# psoc6_01 register map
Vendor: Cypress Semiconductor; Series: psoc6_01; File version: 1.0
CPU: CM4 r0p1, little endian, MPU, FPU, VTOR, 3 interrupt priority bits
Registers are 32-bit, read-write, reset 0x0 unless marked. A register's access mark holds for its fields unless they carry their own. Offsets are from the block's base; [hi:lo] are bit positions; lines under a group give offsets from that group; {n}, {i} and the like mark numbered series; <NAME> marks a mode.

## BLE (part 5 of 5) — Bluetooth Low Energy Subsystem
Base 0x403C0000
0x1F000 BLESS group — Bluetooth Low Energy Subsystem Miscellaneous
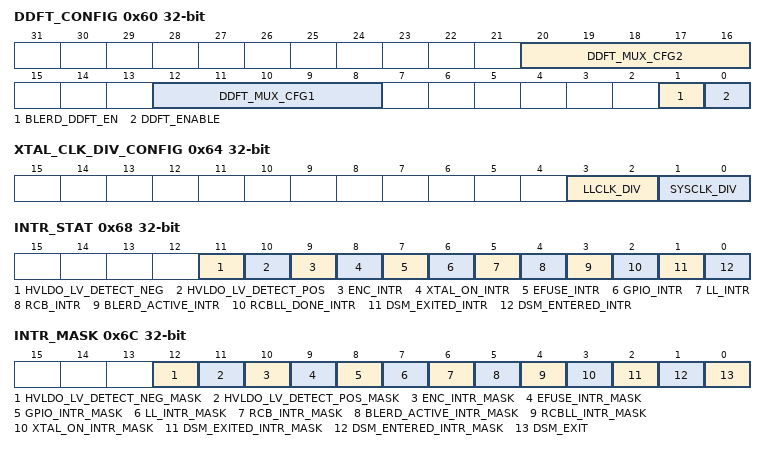
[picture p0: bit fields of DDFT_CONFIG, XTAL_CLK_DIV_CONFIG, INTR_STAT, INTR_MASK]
  0x60 DDFT_CONFIG — BLESS DDFT configuration register
    [20:16] DDFT_MUX_CFG2 — dbg_mux_pin2 selection, combine with BLERD and BLESS 5'h00 blerd_ddft_out[1] 5'h01 rcb_rx_fifo_empty 5'h02 ll_decode_rxdata 5'h03 dbus_tx_en 5'h04 fw_clk_en 5'h05 interrupt_ll_n 5'h06 llh_st_sm 5'h07 llh_st_dsm 5'h08 proc_rx_en 5'h09 rssi_rx_done 5'h0A rx_2mbps 5'h0B rcb_ll_ctrl 5'h0C hv_ldo_byp_n 5'h0D reset_deassert 5'h0E rcb_intr 5'h0F rcb_ll_intr 5'h10 hv_ldo_en_mt (act_stdbyb) 5'h11 hv_ldo_lv_detect_raw 5'h12 bless_rcb_data_in 5'h13 bless_xtal_en_out 5'h14 bless_isolate_n_out 5'h15 bless_reset_n_out 5'h16 bless_ret_ldo_ol_hv_out 5'h17 bless_txd_rxd_out 5'h18 tx_rx_ctrl_sel 5'h19 bless_bpktctl_cy 5'h1A efuse_cs_out 5'h1B efuse_pgm_out 5'h1C efuse_sclk_out 5'h1D hv_ldo_lv_detect_mt 5'h1E enable_ldo 5'h1F enable_ldo_dly
    [12:8] DDFT_MUX_CFG1 — dbg_mux_pin1 selection, combine with BLERD and BLESS 5'h00 blerd_ddft_out[0] 5'h01 rcb_tx_fifo_empty 5'h02 hv_ldo_lv_detect_raw 5'h03 dbus_rx_en 5'h04 1'b0 5'h05 clk_switch_to_sysclk 5'h06 ll_clk_en_sync 5'h07 dsm_entry_stat 5'h08 proc_tx_en 5'h09 rssi_read_start 5'h0A tx_2mbps 5'h0B rcb_bus_busy 5'h0C hv_ldo_en_mt (act_stdbyb) 5'h0D ll_eco_clk_en 5'h0E blerd_reset_assert 5'h0F hv_ldo_byp_n 5'h10 hv_ldo_lv_detect_mt 5'h11 enable_ldo 5'h12 enable_ldo_dly 5'h13 bless_rcb_le_out 5'h14 bless_rcb_clk_out 5'h15 bless_dig_ldo_on_out 5'h16 bless_act_ldo_en_out 5'h17 bless_clk_en_out 5'h18 bless_buck_en_out 5'h19 bless_ret_switch_hv_out 5'h1A efuse_rw_out 5'h1B efuse_avdd_out 5'h1C efuse_config_efuse_mode 5'h1D bless_dbus_tx_en_pad 5'h1E bless_bpktctl_rd 5'h1F 1'b0
    [1] BLERD_DDFT_EN — Enables the DDFT inputs from CYBLERD55 chip 1: DDFT inputs are enabled 0: DDFT inputs are disabled
    [0] DDFT_ENABLE — Enables the DDFT output from BLESS 1: DDFT is enabled 0: DDFT is disabled
  0x64 XTAL_CLK_DIV_CONFIG — Crystal clock divider configuration register
    [3:2] LLCLK_DIV — Link Layer clock pre-divider value. The 24 MHz crystal clock is divided to generate the Link Layer clock. 0: NO_DIV: LLCLK= XTALCLK/1 1: DIV_BY_2: LLCLK= XTALCLK/2 2: DIV_BY_4: LLCLK= XTALCLK/4 3: DIV_BY_8: LLCLK= XTALCLK/8
    [1:0] SYSCLK_DIV — System clock pre-divider value. The 24 MHz crystal clock is divided to generate the system clock. 0: NO_DIV: SYSCLK= XTALCLK/1 1: DIV_BY_2: SYSCLK= XTALCLK/2 2: DIV_BY_4: SYSCLK= XTALCLK/4 3: DIV_BY_8: SYSCLK= XTALCLK/8
  0x68 INTR_STAT — Link Layer interrupt status register
    [11] HVLDO_LV_DETECT_NEG — This interrupt is set on HVLDO LV Detector Fall edge. There is a 1cycle AHB clock glitch filter on the HVLDO LV Detector output
    [10] HVLDO_LV_DETECT_POS — This interrupt is set on HVLDO LV Detector Rise edge. There is a 1cycle AHB clock glitch filter on the HVLDO LV Detector output
    [9] ENC_INTR ro — Encryption Interrupt Triggered
    [8] XTAL_ON_INTR — enabled crystal stable signal rising edge interrupt. The interrupt can be cleared by writing one into this location.
    [7] EFUSE_INTR — This bit when set by efuse controller logic when the efuse read/write is completed
    [6] GPIO_INTR — GPIO interrupt
    [5] LL_INTR ro — LL controller interrupt - Refer to EVENT_INTR register
    [4] RCB_INTR ro — RCB controller Interrupt - Refer to RCB_INTR_STAT register
    [3] BLERD_ACTIVE_INTR — CYBLERD55 is in active mode. RF is active
    [2] RCBLL_DONE_INTR ro — RCB transaction Complete
    [1] DSM_EXITED_INTR — On a firmware request to LL to exit from Deep Sleep Mode, working on LF clock, LL transitions from Deep Sleep Mode and asserts this interrupt when the Deep Sleep clock gater is turned ON. The interrupt can be cleared by writing one into this location.
    [0] DSM_ENTERED_INTR — On a firmware request to LL to enter into state machine, working on LF clock, LL transitions into Deep Sleep Mode and asserts this interrupt. The interrupt can be cleared by writing one into this location.
  0x6C INTR_MASK — Link Layer interrupt mask register
    [12] HVLDO_LV_DETECT_NEG_MASK — Mask for HVLDO LV Detector Fall edge interrupt
    [11] HVLDO_LV_DETECT_POS_MASK — Mask for HVLDO LV Detector Rise edge interrupt
    [10] ENC_INTR_MASK — Mask for Encryption interrupt
    [9] EFUSE_INTR_MASK — This bit enables the efuse interrupt to firmware
    [8] GPIO_INTR_MASK — Mask for GPIO interrupt
    [7] LL_INTR_MASK — Mask for LL interrupt
    [6] RCB_INTR_MASK — Mask for RCB interrupt
    [5] BLERD_ACTIVE_INTR_MASK — Mask for CYBLERD55 Active Interrupt
    [4] RCBLL_INTR_MASK — Mask for RCBLL interrupt
    [3] XTAL_ON_INTR_MASK — Masks the Crystal Stable Interrupt, when disabled.
    [2] DSM_EXITED_INTR_MASK — Masks the DSM Exited Interrupt, when disabled.
    [1] DSM_ENTERED_INTR_MASK — Masks the DSM Entered Interrupt, when disabled.
    [0] DSM_EXIT — When the Link Layer is in Deep Sleep Mode, firmware can set this bit to wake the Link Layer.
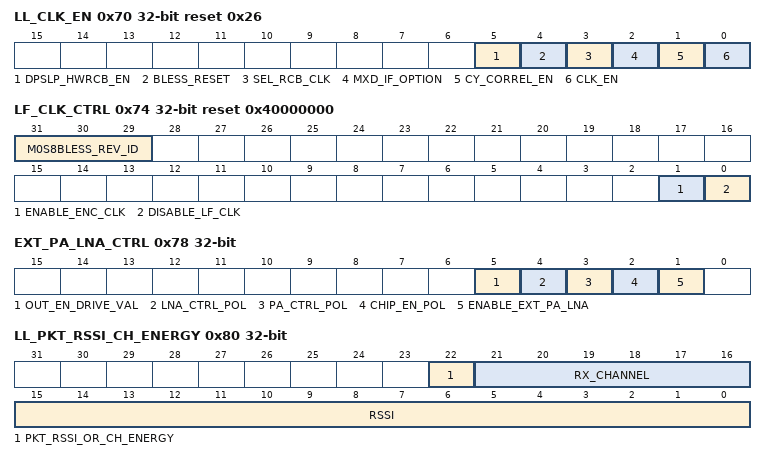
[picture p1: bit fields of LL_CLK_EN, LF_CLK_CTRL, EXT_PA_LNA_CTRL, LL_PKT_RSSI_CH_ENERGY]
  0x70 LL_CLK_EN reset 0x26 — Link Layer primary clock enable
    [5] DPSLP_HWRCB_EN — Controls the DPSLP entry and exit writes to RD and controls the active domain reset and clock. 1 - LL HW controls the RD active domain reset and clock. 0 - The RD active domain reset and clock. Must be controlled by the FW
    [4] BLESS_RESET — 0: No Soft Reset 1: Initiate Soft Reset Setting this bit will reset entire BLESS_VER3
    [3] SEL_RCB_CLK — 0: AHB clock (clk_sys) is used as the clock for RCB access 1: LL clock (clk_eco) is used as the clock for RCB access
    [2] MXD_IF_OPTION — 1: MXD IF option 0: CYBLERD55 correlates Access Code 0: MXD IF option 1: LL correlates Access Code
    [1] CY_CORREL_EN — If MXD_IF option is 1, this bit needs to be set to enable configuring the correlator through BLELL.DPLL_CONFIG register
    [0] CLK_EN — Set this bit 1 to enable the clock to Link Layer.
  0x74 LF_CLK_CTRL reset 0x40000000 — BLESS LF clock control and BLESS revision ID indicator
    [31:29] M0S8BLESS_REV_ID ro — Indicates the m0s8bless IP revision.
    [1] ENABLE_ENC_CLK — This bit is used to enable the clock to the encryption engine 0 - Disable the clock to ENC engine 1 - Enable the clock to ENC engine
    [0] DISABLE_LF_CLK — When set to 1, gates the LF clock input to the Link Layer. Ths is done for extended DSM mode where the DSM state machine needs to be forzen to prevent a default auto exit.
  0x78 EXT_PA_LNA_CTRL — External TX PA and RX LNA control
    [5] OUT_EN_DRIVE_VAL — Configures the drive value on the output enables of PA, LNA and CHI_EN signals 0 - drive 0 on the output enable signals 1 - drive 1 on the output enable signals
    [4] LNA_CTRL_POL — Controls the polarity of the LNA control signal 0 - High enable, low disable 1 - Low enable, High disable
    [3] PA_CTRL_POL — Controls the polarity of the PA control signal 0 - High enable, low disable 1 - Low enable, High disable
    [2] CHIP_EN_POL — Controls the polarity of the chip enable control signal 0 - High enable, low disable 1 - Low enable, High disable
    [1] ENABLE_EXT_PA_LNA — When set to 1, enables the external PA & LNA
  0x80 LL_PKT_RSSI_CH_ENERGY ro — Link Layer Last Received packet RSSI/Channel energy and channel number
    [22] PKT_RSSI_OR_CH_ENERGY — This field indicates if the captured RSSI is for a received packet or is the channel energy
    [21:16] RX_CHANNEL — This field indicates the last channel for which the RSSI is captured
    [15:0] RSSI — This field captures the RSSI of the packet when a packet reception is complete or gives the Channel energy when a Receive cycle is over without packet reception.
  0x84 BT_CLOCK_CAPT ro — BT clock captured on an LL DSM exit
    [15:0] BT_CLOCK — This field captures the LF BT clock captured on an LL DSM exit. This register is valid only when MT_STATUS.LL_CLK_STATE is set. This value may be used to manage the low power entry.
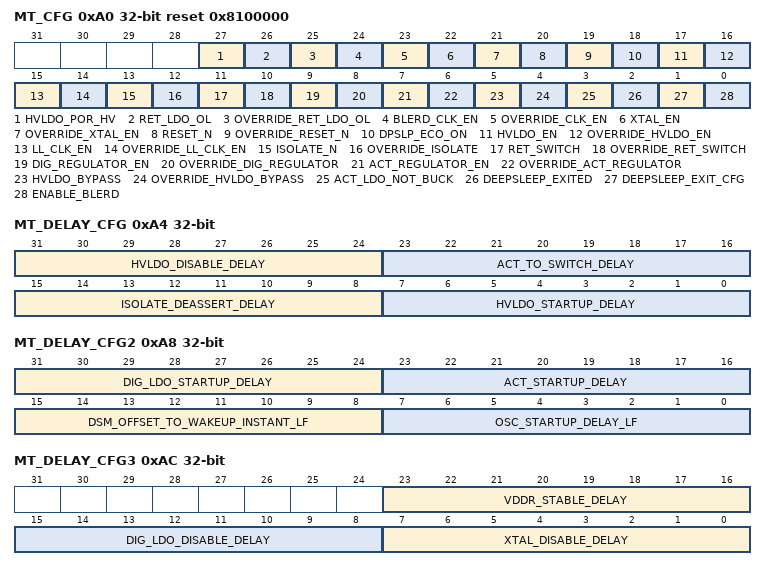
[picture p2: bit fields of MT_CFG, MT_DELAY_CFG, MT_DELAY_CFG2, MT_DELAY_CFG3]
  0xA0 MT_CFG reset 0x8100000 — MT Configuration Register
    [27] HVLDO_POR_HV — Reset for HVLDO 1'b1 - HVLDO Disabled 1'b0 - HVLDO Enabled
    [26] RET_LDO_OL — Overrie value for CYBLERD55 RET_LDO_OL_HV
    [25] OVERRIDE_RET_LDO_OL — This register should be set to override the HW generated RET_LDO_OL_HV to CYBLERD55. When set CLK_EN is used.
    [24] BLERD_CLK_EN — Overrie value for CYBLERD55 CLK_EN
    [23] OVERRIDE_CLK_EN — This register should be set to override the HW generated CLK_EN to CYBLERD55. When set CLK_EN is used.
    [22] XTAL_EN — Overrie value for CYBLERD55 XTAL_EN
    [21] OVERRIDE_XTAL_EN — This register should be set to override the HW generated XTAL_EN to CYBLERD55. When set XTAL_EN is used.
    [20] RESET_N — Overrie value for CYBLERD55 RESET_N
    [19] OVERRIDE_RESET_N — This register should be set to override the HW generated reset to CYBLERD55. When set RESET_N is used.
    [18] DPSLP_ECO_ON — This bit when set indicates that ECO clock should be kept on even in BLESS DPSLP. This bit must be toggled only when the Link Layer is active.
    [17] HVLDO_EN — Overrie value for HVLDO enable 1'b1: switch to Active LDO 1'b0: switch to standby LDO
    [16] OVERRIDE_HVLDO_EN — This register should be set to override the HW generated enable to HVLSO. When set HVLDO_EN is used.
    [15] LL_CLK_EN — Override value for LL Clock gate
    [14] OVERRIDE_LL_CLK_EN — This register should be set to override the HW generated ECO Clock gate. When set LL_CLK_EN is used to gate the clock
    [13] ISOLATE_N — Override value for isolation to CYBLERD55
    [12] OVERRIDE_ISOLATE — This register should be set to override the HW generated isolation signal to CYBLERD55. When set ISOLATE_N is driven to the IP
    [11] RET_SWITCH — Override value for RET_SWITCH
    [10] OVERRIDE_RET_SWITCH — This register should be set to override the HW generated signal to the retention switch of CYBLERD55. When set OVERRIDE_RET_SWITCH is driven to the IP
    [9] DIG_REGULATOR_EN — Override value for digital regulator of CYBLERD55
    [8] OVERRIDE_DIG_REGULATOR — This register should be set to override the HW generated signal to Digital regulator of CYBLERD55. When set DIG_REGULATOR_EN is driven to CYBLERD55
    [7] ACT_REGULATOR_EN — Override value for ACT_LDO_EN/BUCK_EN
    [6] OVERRIDE_ACT_REGULATOR — This register should be set to override the HW generated signal to enable ACTIVE_LDO/BUCK. When set ACT_REGULATOR_EN is driven to CYBLERD55
    [5] HVLDO_BYPASS — Override value for HVLDO BYPASS 1'b0: bypass the HVLDO 1'b1: Do not bypass the HVLDO
    [4] OVERRIDE_HVLDO_BYPASS — This register should be set to override the HW generated signal to HVLDO. When set HVLDO_BYPASS is driven to the IP
    [3] ACT_LDO_NOT_BUCK — This register bit specifies whether the Active LDO or BUCK in CYBLERD55 is used in active mode
    [2] DEEPSLEEP_EXITED — This register bit is used by FW to indicate that PSoC is out of DeepSleep 1'b0 - PSoC in DeepSleep 1'b1 - PSoC out of DeepSleep This bit is cleared by HW on exit from DPSLP
    [1] DEEPSLEEP_EXIT_CFG — This register bit indicates the source for PSoC DeepSleep exit to BLESS 1'b0 - act_power_good from SRSS indicates PSoC DeepSleep exit 1'b1 - MT_CFG.DEEPSLEEP_EXITED indicates PSoC DeepSleep exit
    [0] ENABLE_BLERD — This register bit needs to be set to enable CYBLERD55 1'b1 - CYBLERD55 enabled 1'b0 - CYBLERD55 disabled On power up this bit needs to be set to make CYBLERD55 active.
  0xA4 MT_DELAY_CFG — MT Delay configuration for state transitions
    [31:24] HVLDO_DISABLE_DELAY — This register specifies the time from disabling XTAL to switching of the HVLDO.
    [23:16] ACT_TO_SWITCH_DELAY — This register specifies the time from assertion of ISOLATE_N to switching the CYBLERD55 logic to Retention LDO
    [15:8] ISOLATE_DEASSERT_DELAY — This register specifies the time from switching the CYBLERD55 logic to Active regulator to removal of ISOLATE_N
    [7:0] HVLDO_STARTUP_DELAY — This register specifies the startup delay for the HVLDO interms of number of LF Clock cycles. FW has to program this register based on the selected LF clock frequency
  0xA8 MT_DELAY_CFG2 — MT Delay configuration for state transitions
    [31:24] DIG_LDO_STARTUP_DELAY — This register specifes the Digital LDO startup time in CYBLERD55.The delay is in terms of LF Clock cycles. FW has to program this register based on the selected LF clock frequency. The logic in CYBLERD55 is switched to Active mode Regulator after this (ACT_STARTUP_DELAY + DIG_LDO_STARTUP_DELAY)
    [23:16] ACT_STARTUP_DELAY — This register specifes the Active Regulator startup time in CYBLERD55. The delay is in terms of LF Clock cycles. FW has to program this register based on the selected LF clock frequency. The digital LDO will be turned on after this time elapses
    [15:8] DSM_OFFSET_TO_WAKEUP_INSTANT_LF — This register specifies the pre-processing time required in Link Layer. This is esentially the time from CLK_EN (ungating clock in CYBLERD55) to the time when logic in CYBLERD55 is switched to Active mode Regulator.The delay is in terms of LF Clock cycles. FW has to program this register based on the selected LF clock frequency. This is equivalent to Link Layer register WAKEUP_CONFIG.DSM_OFFSET_TO_WAKEUP_INSTANT_LF, but is specified in LF cycles.
    [7:0] OSC_STARTUP_DELAY_LF — This register specifies the time for OSC Startup. After this delay, clock is enabled to the link layer. Clock is enabled after OSC_STARTUP_DELAY + 1 LF clock cycles. If PSoC was in DPSLP when XTAL is enabled, then the wakeup delay will be OSC_STARTUP_DELAY + 1 + PSoC Wakeup time. Minimum value to be programmed in 1. This is equivalent to Link Layer register WAKEUP_CONFIG.OSC_STARTUP_DELAY, but is specified in LF cycles
  0xAC MT_DELAY_CFG3 — MT Delay configuration for state transitions
    [23:16] VDDR_STABLE_DELAY — This field holds the delay after HVLDO Startup to VDDR Stable. Refer to memo AKK-410
    [15:8] DIG_LDO_DISABLE_DELAY — This field holds the delay from the time of diabling Digital LDO to the time at which ACTIVE regulator is disabled
    [7:0] XTAL_DISABLE_DELAY — This register specifies the time from switching of logic to Retention LDO in CYBLERD55 to XTAL Disable. This should include the post processing time The delay is in terms of LF Clock cycles. FW has to program this register based on the selected LF clock frequency. At the minimum XTAL_DISABLE_DELAY should be the sum of DIG_LDO_DISABLE_DELAY and the powerdown time of ACTIVE_LDO
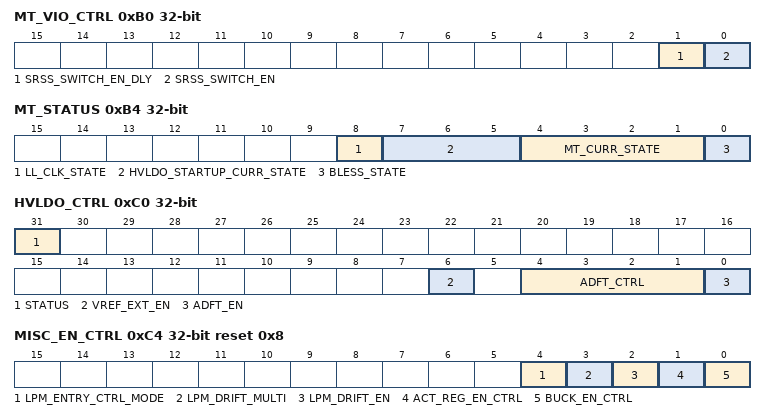
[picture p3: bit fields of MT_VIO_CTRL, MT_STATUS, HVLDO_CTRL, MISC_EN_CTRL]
  0xB0 MT_VIO_CTRL — MT Configuration Register to control VIO switches
    [1] SRSS_SWITCH_EN_DLY — Enable to turn on HVLDO (All legs). This must be enabled 64us after enabling SRSS_SWITCH_EN 1'b0 - Switch is turned off 1'b1 - Switch is turned on
    [0] SRSS_SWITCH_EN — Enable to turn on HVLDO (One leg) 1'b0 - Switch is turned off 1'b1 - Switch is turned on
  0xB4 MT_STATUS ro
    [8] LL_CLK_STATE — This bit indicates when the Link Layer registers are accessible upon a DSM exit. This bit should not be used after a DSM entry command has been issued. 1'b0 - Link Layer clock is not available 1'b1 - Link Layer clock is active
    [7:5] HVLDO_STARTUP_CURR_STATE — This register reflects the current state of the HVLDO Startup FSM 3'h0 - HVLDO_OFF 3'h1 - HVLDO_WAIT 3'h2 - HVLDO_SAMPLE 3'h3 - HVLDO_ENABLED 3'h4 - HVLDO_SET_BYPASS
    [4:1] MT_CURR_STATE — This register reflects the current state of the MT FSM 4'h0 - IDLE 4'h1 - BLERD_DEEPSLEEP 4'h2 - HVLDO_STARTUP 4'h3 - WAIT_CLK 4'h4 - BLERD_IDLE 4'h5 - SWITCH_EN 4'h6 - ACTIVE 4'h7 - ISOLATE 4'h8 - WAIT_IDLE 4'h9 - XTAL_DISABLE 4'hA - HVLDO_DISABLE
    [0] BLESS_STATE — 1'b0 - BLESS in DPSLP state 1'b1 - BLESS in ACTIVE state
  0xB8 PWR_CTRL_SM_ST ro — Link Layer Power Control FSM Status Register
    [3:0] PWR_CTRL_SM_CURR_STATE — This register reflects the current state of the LL Power Control FSM 4'h0 - IDLE 4'h1 - SLEEP 4'h2 - DEEP_SLEEP 4'h4 - WAIT_OSC_STABLE 4'h5 - INTR_GEN 4'h6 - ACTIVE 4'h7 - REQ_RF_OFF
  0xC0 HVLDO_CTRL — HVLDO Configuration register
    [31] STATUS ro — hvldo LV detect status
    [6] VREF_EXT_EN — Vref ext input enable.
    [4:1] ADFT_CTRL — ADFT select
    [0] ADFT_EN — ADFT enable
  0xC4 MISC_EN_CTRL reset 0x8 — Radio Buck and Active regulator enable control
    [4] LPM_ENTRY_CTRL_MODE — Controls the LPM entry control mode 1 - LPM can be entered in the same slot as the previous LPM exit 0 - LPM must not be entered in the same slot or the subsequent slot as the last LPM exit
    [3] LPM_DRIFT_MULTI — Controls the LPM drift multi level compensation. 1 - Enables the LPM drift multi comp 0 - Disables the LPM drift multi comp
    [2] LPM_DRIFT_EN — Controls the LPM drift calculation. 1 - Enables the LPM drift mod 0 - Disables the LPM drift mod
    [1] ACT_REG_EN_CTRL — Active regulator enable control. This must be programmed before enabling the Radio. 1'b0 - Active regulator enable output to radio is tied to 0 1'b1 - Active regulator enable output to radio is controlled from Mode transition FSM
    [0] BUCK_EN_CTRL — Buck enable control. This must be programmed before enabling the Radio. 1'b1 - Buck enable output to radio is tied to 0 1'b0 - Buck enable output to radio is controlled from Mode transition FSM
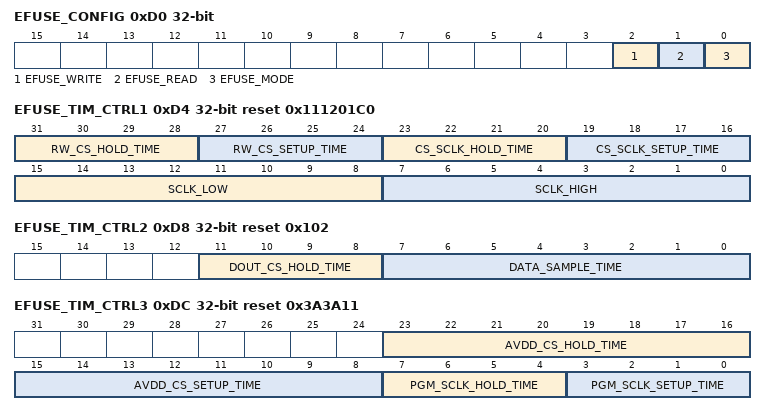
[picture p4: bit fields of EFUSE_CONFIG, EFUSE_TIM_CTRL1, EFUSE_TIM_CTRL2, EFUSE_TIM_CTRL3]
  0xD0 EFUSE_CONFIG — EFUSE mode configuration register
    [2] EFUSE_WRITE — This bit when set by firmware enables the write to EFUSE macro. It is cleared when the efuse write is completed
    [1] EFUSE_READ — This bit when set by firmware enables the read from EFUSE macro. It is cleared when the efuse read is completed
    [0] EFUSE_MODE — This register enables the efuse mode in m0s8bless_ver3
  0xD4 EFUSE_TIM_CTRL1 reset 0x111201C0 — EFUSE timing control register (common for Program and Read modes)
    [31:28] RW_CS_HOLD_TIME — This field decides hold time between RW & CS (THR_RW: in read mode) or RW & AVDD (THP_RW: in Program mode). THR_RW: RW to CS hold time out of Read mode THP_RW: RW to AVDD hold time out of program mode
    [27:24] RW_CS_SETUP_TIME — This field decides setup time between RW & CS (TSR_RW: in read mode) or RW & AVDD (TSP_RW: in Program mode). TSR_RW: RW to CS setup time into Read mode TSP_RW: RW to AVDD setup time into program mode
    [23:20] CS_SCLK_HOLD_TIME — This register specifies the hold time between CS and SCLK (THR_CLK)
    [19:16] CS_SCLK_SETUP_TIME — This register specifies the setup time between CS and SCLK (TSR_CLK)
    [15:8] SCLK_LOW — Duration of SCLK LOW (TCLKP_R) or TCKLP_P
    [7:0] SCLK_HIGH — Decides the duration of TPGM (in Program mode) or TCKHP (in Read mode) TPGM: Burning Time TCKHP : SCLK high Period
  0xD8 EFUSE_TIM_CTRL2 reset 0x102 — EFUSE timing control Register (for Read)
    [11:8] DOUT_CS_HOLD_TIME — Wait time DOUT to CS hold time out of read mode (TDQH)
    [7:0] DATA_SAMPLE_TIME — This register specifies the time for data sampling from SCLK HIGH (TCKDQ_H)
  0xDC EFUSE_TIM_CTRL3 reset 0x3A3A11 — EFUSE timing control Register (for Program)
    [23:16] AVDD_CS_HOLD_TIME — AVDD to CS hold time out of program mode (THP_AVDD_CS)
    [15:8] AVDD_CS_SETUP_TIME — AVDD to CS setup time into program mode (TSP_AVDD_CS)
    [7:4] PGM_SCLK_HOLD_TIME — PGM to SCLK hold time (TH_PGM)
    [3:0] PGM_SCLK_SETUP_TIME — PGM to SCLK setup time (TS_PGM) PGM_SCLK_SETUP_TIME <CS_SCLK_SETUP_TIME
  0xE0 EFUSE_RDATA_L ro — EFUSE Lower read data
    [31:0] DATA — This register has the read value from the Efuse macro, fuse bits[31:0]
  0xE4 EFUSE_RDATA_H ro — EFUSE higher read data
    [31:0] DATA — This register has the read value from the Efuse macro, fuse bits[63:32]
  0xE8 EFUSE_WDATA_L — EFUSE lower write word
    [31:0] DATA — This register has the write value to the Efuse macro, fuse bits[31:0]
  0xEC EFUSE_WDATA_H — EFUSE higher write word
    [31:0] DATA — This register has the write value to the Efuse macro, fuse bits[63:32]
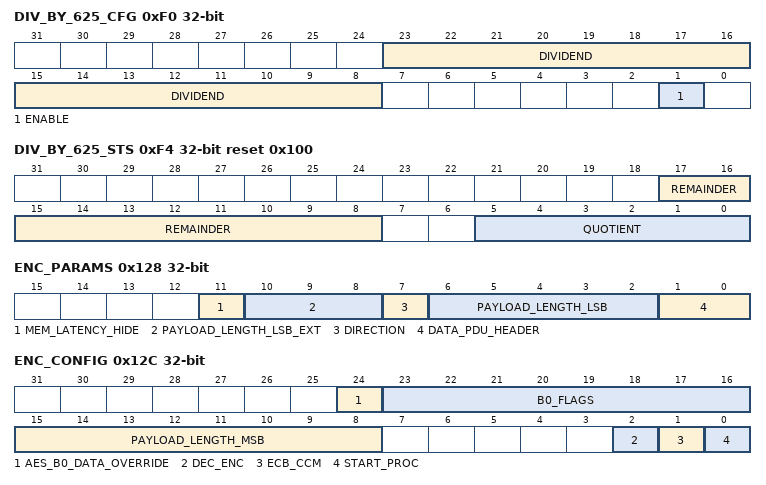
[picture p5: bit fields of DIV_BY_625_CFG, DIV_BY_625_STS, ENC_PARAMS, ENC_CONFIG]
  0xF0 DIV_BY_625_CFG — Divide by 625 for FW Use
    [23:8] DIVIDEND — This field holds the dividend
    [1] ENABLE — This bit enables the divider for use by FW 1'b0 - divider used by LL 1'b1 - divider can be used by FW This divider can only be used in MMMS mode. Do not enable for legacy operation
  0xF4 DIV_BY_625_STS ro reset 0x100 — Output of divide by 625 divider
    [17:8] REMAINDER — Remainder value from the divider. Available 1 cycle after dividend is programmed.
    [5:0] QUOTIENT — Quotient value from the divider. Available 1 cycle after dividend is programmed.
  0x100 PACKET_COUNTER0
    [31:0] PACKET_COUNTER_LOWER — Lower 32-bits of the packet counter value passed as part of Nonce for the packet to be encrypted.
  0x104 PACKET_COUNTER2
    [7:0] PACKET_COUNTER_UPPER — Upper 8 bits of the packet counter value passed as part of Nonce for the packet to be encrypted.
  0x108 IV_MASTER0 — Master Initialization Vector 0
    [31:0] IV_MASTER — This is the IVm field, which contains the master's portion of the initialization vector.
  0x10C IV_SLAVE0 — Slave Initialization Vector 0
    [31:0] IV_SLAVE — This is the IVs field, which contains the slave's portion of the initialization vector.
  {0x110+4j} ENC_KEY[{j}] (j=0..3) wo — Encryption Key register 0-3
    [31:0] ENC_KEY — The encryption key / session key which is used in ECB encryption, CCM encryption and CCM decryption.
  0x120 MIC_IN0 — MIC input register
    [31:0] MIC_IN — This is the MIC field used for CCM decryption.
  0x124 MIC_OUT0 ro — MIC output register
    [31:0] MIC_OUT — This is the MIC generated during CCM encryption.
  0x128 ENC_PARAMS — Encryption Parameter register
    [11] MEM_LATENCY_HIDE — Controls the encryption memory access mode. Valid only when DLE is enabled. 0 - The AES is idle while memory fetch/store in progress. 1- The AES is pipelined while memory fetch/store in progress.
    [10:8] PAYLOAD_LENGTH_LSB_EXT — 3 Most significant bits of the LS byte of the length of the input data. Valid only when DLE is enabled. When DLE is enabled total ENC payload length = {PAYLOAD_LENGTH_LSB_EXT, PAYLOAD_LENGTH_LSB}
    [7] DIRECTION — The directionBit shall be set to '1' for Data Channel PDUs sent by the master and set to '0' for Data Channel PDUs sent by the slave.
    [6:2] PAYLOAD_LENGTH_LSB — Length of the input data.
    [1:0] DATA_PDU_HEADER — LLID of the packet.
  0x12C ENC_CONFIG — Encryption Configuration
    [24] AES_B0_DATA_OVERRIDE — Configuration to use B0 DATA provided by FW for CCM computation
    [23:16] B0_FLAGS — LS byte of the input data when B0 needs to be completely configurable. Valid only when AES_B0_DATA_OVERRIDE is enabled.
    [15:8] PAYLOAD_LENGTH_MSB — MS byte of the length of the input data when B0 needs to be completely configurable. Valid only when AES_B0_DATA_OVERRIDE is enabled. When AES_B0_DATA_OVERRIDE is enabled total ENC payload length = {PAYLOAD_LENGTH_MSB, PAYLOAD_LENGTH_MSB, PAYLOAD_LENGTH}
    [2] DEC_ENC — Decryption/Encryption 0 - Encrypt 1 - Decrypt
    [1] ECB_CCM — 0 - CCM 1 - ECB
    [0] START_PROC — 1 Start the AES processing
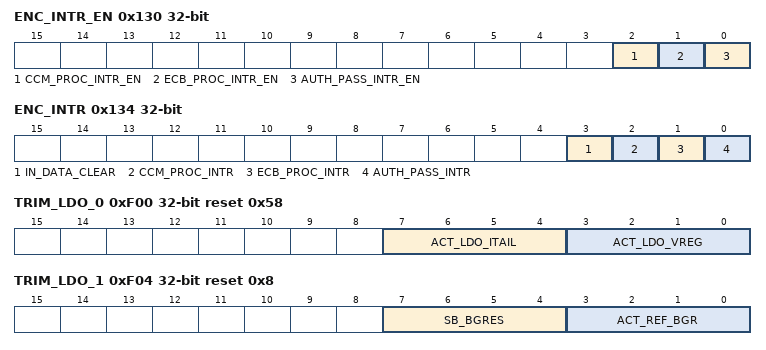
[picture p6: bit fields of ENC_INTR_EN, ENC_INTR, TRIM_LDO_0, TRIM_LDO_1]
  0x130 ENC_INTR_EN — Encryption Interrupt enable
    [2] CCM_PROC_INTR_EN — CCM processed interupt enable 0 - Disable 1 - Enable
    [1] ECB_PROC_INTR_EN — ECB processed interrupt enable 0 - Disable 1 - Enable
    [0] AUTH_PASS_INTR_EN — Authentication interrupt enable 0 - Disable 1 - Enable
  0x134 ENC_INTR — Encryption Interrupt status and clear register
    [3] IN_DATA_CLEAR — Clears the input data. Used for Zero padding of encryption for less than block sized data.
    [2] CCM_PROC_INTR — CCM processed interrupt. Writing 1 to this register clears the interrupt
    [1] ECB_PROC_INTR — ECB processed interrupt. Writing 1 to this register clears the interrupt.
    [0] AUTH_PASS_INTR — Authentication interrupt. 0x1- indicates MIC matched 0x0 -indicated MIC mismatched Writing 1 to this register clears the interrupt.
  {0x140+4j} B1_DATA_REG[{j}] (j=0..3) — Programmable B1 Data register (0-3)
    [31:0] B1_DATA — Programmable B1 Data register
  0x150 ENC_MEM_BASE_ADDR — Encryption memory base address
    [31:0] ENC_MEM — Data values written to Enc memory are written as 16-bit wide data. This memory is valid only if DLE is set.
  0xF00 TRIM_LDO_0 reset 0x58 — LDO Trim register 0
    [7:4] ACT_LDO_ITAIL — To trim the bias currents for all the active mode blocks
    [3:0] ACT_LDO_VREG — To trim the regulated voltage in steps of 25mV typically
  0xF04 TRIM_LDO_1 reset 0x8 — LDO Trim register 1
    [7:4] SB_BGRES — To trim standby regulator reference voltage
    [3:0] ACT_REF_BGR — To trim active regulator reference voltage
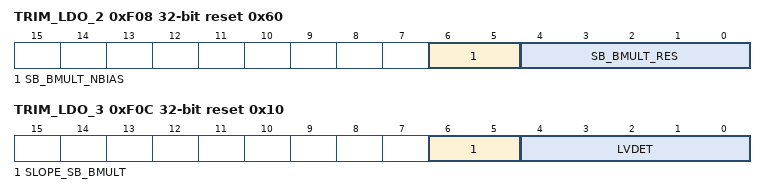
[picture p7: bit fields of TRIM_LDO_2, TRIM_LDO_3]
  0xF08 TRIM_LDO_2 reset 0x60 — LDO Trim register 2
    [6:5] SB_BMULT_NBIAS — To trim standby regulator beta-multiplier current
    [4:0] SB_BMULT_RES — To trim standby regulator beta-multiplier current
  0xF0C TRIM_LDO_3 reset 0x10 — LDO Trim register 3
    [6:5] SLOPE_SB_BMULT — To trim standby regulator beta-multiplier temp-co slope
    [4:0] LVDET — To trim the trip points of the LV-Detect block
  {0xF10+4j} TRIM_MXD[{j}] (j=0..3) — MXD die Trim registers
    [7:0] MXD_TRIM_BITS
  0xF30 TRIM_LDO_4 — LDO Trim register 4
    [7:0] T_LDO — To debug post layout or post silicon
  0xF34 TRIM_LDO_5 — LDO Trim register 5
    [7:0] RSVD
